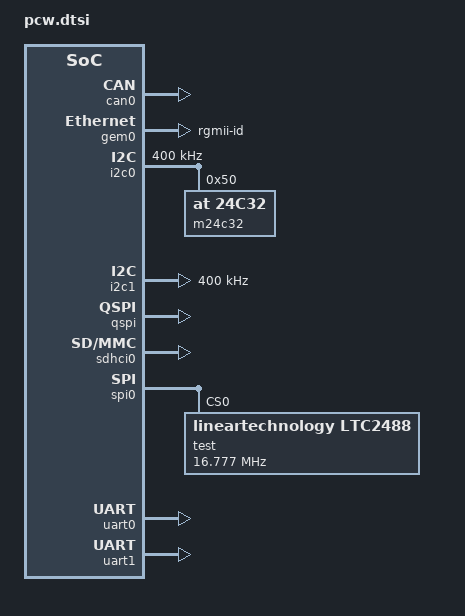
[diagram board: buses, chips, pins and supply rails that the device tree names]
/*
 * CAUTION: This file is automatically generated by Xilinx.
 * Version:  
 * Today is: Wed Sep 11 23:41:00 2019
 */


/ {
	cpus {
		cpu@0 {
			operating-points = <666666 1000000 333333 1000000>;
		};
	};
};
&can0 {
	status = "okay";
};
&gem0 {
	phy-mode = "rgmii-id";
	status = "okay";
	xlnx,ptp-enet-clock = <0x69f6bcb>;
};
&gpio0 {
	emio-gpio-width = <64>;
	gpio-mask-high = <0x0>;
	gpio-mask-low = <0x5600>;
};
&i2c0 {
	clock-frequency = <400000>;
	status = "okay";
        m24c32@50 {
                   compatible = "at,24c32";
                   reg = <0x50>;
       };
};
&i2c1 {
	clock-frequency = <400000>;
	status = "okay";
};
&intc {
	num_cpus = <2>;
	num_interrupts = <96>;
};
&qspi {
	is-dual = <0>;
	num-cs = <1>;
	spi-rx-bus-width = <4>;
	spi-tx-bus-width = <4>;
	status = "okay";
};
&sdhci0 {
        status = "okay";
        xlnx,has-cd = <0x0>;
        xlnx,has-power = <0x0>;
        xlnx,has-wp = <0x0>;
};
&spi0 {
	is-decoded-cs = <0>;
	num-cs = <1>;
	status = "okay";
        test@1{
              compatible = "lineartechnology,ltc2488";
              spi-max-frequency = <0x1000000>;
              reg = <0x0>;
        };
};
&uart0 {
	device_type = "serial";
	port-number = <0>;
	status = "okay";
};
&uart1 {
	device_type = "serial";
	port-number = <1>;
	status = "okay";
};
&clkc {
	fclk-enable = <0x1>;
	ps-clk-frequency = <33333333>;
};
